# axidma register map
File version: 7.1
Registers are 32-bit, read-write, reset 0x0 unless marked. A register's access mark holds for its fields unless they carry their own. Offsets are from the block's base; [hi:lo] are bit positions; 'fields as' and 'values as' point back to an identical list.

## AXI_DMA — AXI Direct Memory Access
Base 0x60100000
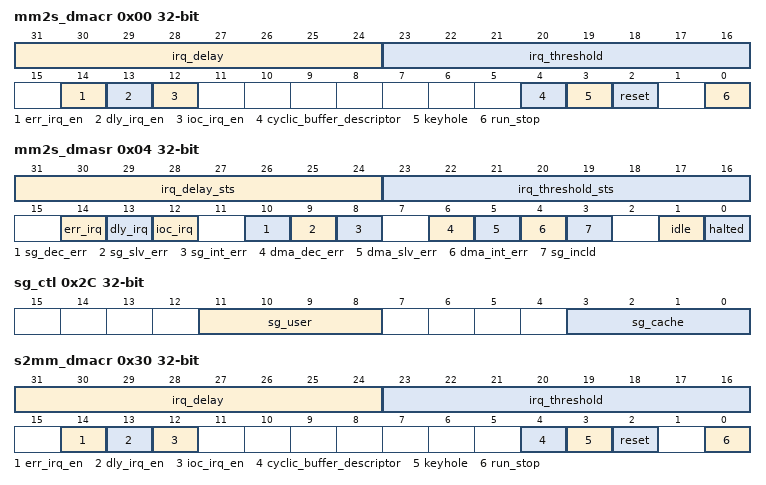
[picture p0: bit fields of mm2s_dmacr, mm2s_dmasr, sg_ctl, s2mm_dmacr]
0x00 mm2s_dmacr — MM2S DMA Control register
  [31:24] irq_delay — Interrupt Delay Time Out
  [23:16] irq_threshold — Interrupt Threshold
  [14] err_irq_en — Interrupt on Error Interrupt Enable
    0=DISABLE; 1=ENABLE
  [13] dly_irq_en — Interrupt on Delay Timer Interrupt Enable
    0=DISABLE; 1=ENABLE
  [12] ioc_irq_en — Interrupt on Complete (IOC) Interrupt Enable
    0=DISABLE; 1=ENABLE
  [4] cyclic_buffer_descriptor — When set to 1, the DMA operates in Cyclic Buffer Descriptor (BD) mode without any user intervention
    0=DISABLE; 1=ENABLE
  [3] keyhole — Keyhole Read
    0=DISABLE; 1=ENABLE
  [2] reset — Soft reset for resetting the AXI DMA core
    0=NORMAL; 1=RESET
  [0] run_stop — Run / Stop control for controlling running and stopping of the DMA channel.
    0=STOP; 1=RUN
0x04 mm2s_dmasr — MM2S DMA Status register
  [31:24] irq_delay_sts — Interrupt Delay Time Status. Indicates current interrupt delay time value.
  [23:16] irq_threshold_sts — Interrupt Threshold Status. Indicates current interrupt threshold value.
  [14] err_irq — Interrupt on Error
    0=NO_INTR; 1=DETECTED
  [13] dly_irq — Interrupt on Delay Timer
    0=NO_INTR; 1=DETECTED
  [12] ioc_irq — Interrupt on Complete (IOC)
    0=NO_INTR; 1=DETECTED
  [10] sg_dec_err — Scatter Gather Decode Error. This error occurs if CURDESC_PTR and/or NXTDESC_PTR points to an invalid address.
    0=NO_ERR; 1=DETECTED
  [9] sg_slv_err — Scatter Gather Slave Error. This error occurs if the slave read from on the Memory Map interface issues a Slave error.
    0=NO_ERR; 1=DETECTED
  [8] sg_int_err — Scatter Gather Internal Error. This error occurs if a descriptor with the “Complete bit” already set is fetched.
    0=NO_ERR; 1=DETECTED
  [6] dma_dec_err — DMA Decode Error. This error occurs if the address request points to an invalid address.
    0=NO_ERR; 1=DETECTED
  [5] dma_slv_err — DMA Slave Error. This error occurs if the slave read from the Memory Map interface issues a Slave Error.
    0=NO_ERR; 1=DETECTED
  [4] dma_int_err — DMA Internal Error. Internal error occurs if the buffer length specified in the fetched descriptor is set to 0.
    0=NO_ERR; 1=DETECTED
  [3] sg_incld — Scatter Gather Engine Included. DMASR.SGIncld = 1 indicates the Scatter Gather engine is included and the AXI DMA is configured for Scatter Gather mode.
    0=SG_DISABLED; 1=SG_ENABLED
  [1] idle — DMA Channel Idle. Indicates the state of AXI DMA operations.
    0=NOT_IDLE; 1=IDLE
  [0] halted — DMA Channel Halted. Indicates the run/stop state of the DMA channel.
    0=RUNNING; 1=HALTED
0x08 mm2s_curdesc — MM2S Current Descriptor Pointer. Lower 32 bits of the address.
  [31:6] curdesc_ptr — Indicates the pointer of the current descriptor being worked on.
0x0C mm2s_curdesc_msb — MM2S Current Descriptor Pointer. Upper 32 bits of the address.
  [31:0] curdesc_ptr — Indicates the pointer of the current descriptor being worked on.
0x10 mm2s_taildesc — MM2S Tail Descriptor Pointer. Lower 32 bits of the address.
  [31:6] taildesc_ptr — Indicates the pause pointer in a descriptor chain.
0x14 mm2s_taildesc_msb — MM2S Tail Descriptor Pointer. Upper 32 bits of the address.
  [31:0] taildesc_ptr — Indicates the pause pointer in a descriptor chain.
0x18 mm2s_sa — MM2S Source Address. Lower 32 bits of the address.
  [31:0] src_addr — Indicates the source address AXI DMA reads from to transfer data to AXI4-Stream on the MM2S Channel.
0x1C mm2s_sa_msb — MM2S Source Address. Upper 32 bits of the address.
  [31:0] src_addr — Indicates the MSB 32 bits of the source address AXI DMA reads from totransfer data to AXI4-Stream on the MM2S Channel.
0x28 mm2s_length — MM2S Transfer Length (Bytes)
  [25:0] length — Indicates the number of bytes to transfer for the MM2S channel.
0x2C sg_ctl — Scatter/Gather User and Cache
  [11:8] sg_user — Scatter/Gather User Control. Values written in this register reflect on the m_axi_sg_aruser and m_axi_sg_awuser signals of the M_AXI_SG interface.
  [3:0] sg_cache — Scatter/Gather Cache Control. Values written in this register reflect on the m_axi_sg_arcache and m_axi_sg_awcache signals of the M_AXI_SG interface.
0x30 s2mm_dmacr — S2MM DMA Control register
  fields as mm2s_dmacr
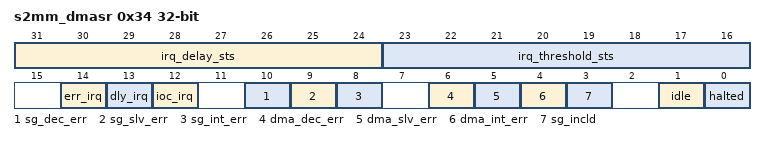
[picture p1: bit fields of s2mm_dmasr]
0x34 s2mm_dmasr — S2MM DMA Status register
  fields as mm2s_dmasr
0x38 s2mm_curdesc — S2MM Current Descriptor Pointer. Lower 32 address bits.
  [31:6] curdesc_ptr — Indicates the pointer of the current Buffer Descriptor being worked on.
0x3C s2mm_curdesc_msb — S2MM Current Descriptor Pointer. Upper 32 address bits.
  [31:0] curdesc_ptr — Indicates the pointer of the current Buffer Descriptor being worked on.
0x40 s2mm_taildesc — S2MM Tail Descriptor Pointer. Lower 32 address bits.
  fields as mm2s_taildesc
0x44 s2mm_taildesc_msb — S2MM Tail Descriptor Pointer. Upper 32 address bits.
  fields as mm2s_taildesc_msb
0x48 s2mm_da — S2MM Destination Address. Lower 32 bit address
  [31:0] dst_addr — Indicates the destination address the AXI DMA writes to transfer data from AXI4-Stream on S2MM Channel.
0x4C s2mm_da_msb — S2MM Destination Address. Upper 32 bit address.
  [31:0] dst_addr — Indicates the MSB 32 bits of the destination address the AXI DMA writes to transfer data from AXI4-Stream on the S2MM Channel.
0x58 s2mm_length — S2MM Buffer Length (Bytes)
  [0] ctl_lt_initialize_to_tx
    0=DISABLE; 1=ENABLE
